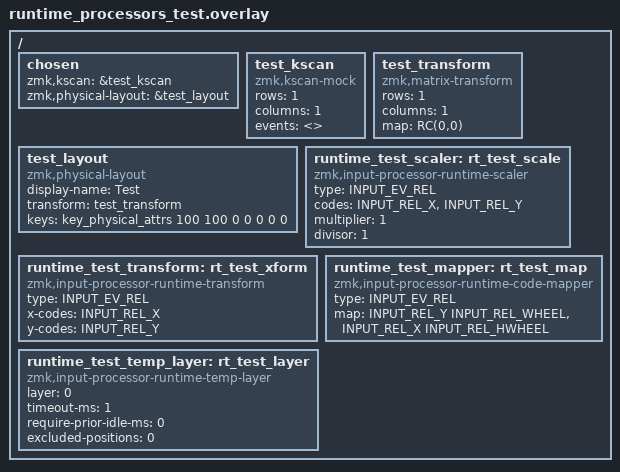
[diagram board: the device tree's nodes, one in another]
#include <zephyr/dt-bindings/input/input-event-codes.h>
#include <dt-bindings/zmk/matrix_transform.h>
#include <physical_layouts.dtsi>

/ {
    /*
     * One mock key and no hardware. ZMK needs a kscan and a transform to size
     * the keymap, and a Studio build accepts only a physical layout with keys.
     */
    chosen {
        zmk,kscan = &test_kscan;
        zmk,physical-layout = &test_layout;
    };

    test_kscan: test_kscan {
        compatible = "zmk,kscan-mock";
        rows = <1>;
        columns = <1>;
        events = <>;
    };

    test_transform: test_transform {
        compatible = "zmk,matrix-transform";
        rows = <1>;
        columns = <1>;
        map = <RC(0,0)>;
    };

    test_layout: test_layout {
        compatible = "zmk,physical-layout";
        display-name = "Test";
        transform = <&test_transform>;
        keys = <&key_physical_attrs 100 100 0 0 0 0 0>;
    };

    runtime_test_scaler: rt_test_scale {
        compatible = "zmk,input-processor-runtime-scaler";
        #input-processor-cells = <0>;
        type = <INPUT_EV_REL>;
        codes = <INPUT_REL_X>, <INPUT_REL_Y>;
        multiplier = <1>;
        divisor = <1>;
    };

    runtime_test_transform: rt_test_xform {
        compatible = "zmk,input-processor-runtime-transform";
        #input-processor-cells = <0>;
        type = <INPUT_EV_REL>;
        x-codes = <INPUT_REL_X>;
        y-codes = <INPUT_REL_Y>;
    };

    runtime_test_mapper: rt_test_map {
        compatible = "zmk,input-processor-runtime-code-mapper";
        #input-processor-cells = <0>;
        type = <INPUT_EV_REL>;
        map = <INPUT_REL_Y INPUT_REL_WHEEL>,
              <INPUT_REL_X INPUT_REL_HWHEEL>;
    };

    runtime_test_temp_layer: rt_test_layer {
        compatible = "zmk,input-processor-runtime-temp-layer";
        #input-processor-cells = <0>;
        layer = <0>;
        timeout-ms = <1>;
        require-prior-idle-ms = <0>;
        excluded-positions = <0>;
    };
};
